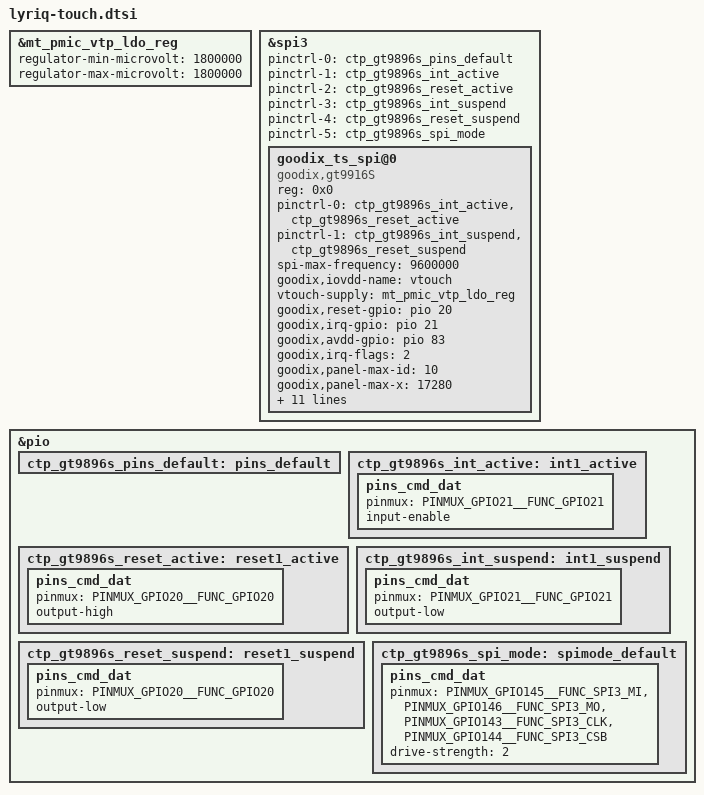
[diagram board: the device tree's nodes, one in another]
/* SPDX-License-Identifier: GPL-2.0 */
/*
 * Copyright (c) 2019 MediaTek Inc.
*/
/* TOUCH start */
&mt_pmic_vtp_ldo_reg {
	regulator-min-microvolt = <1800000>;
	regulator-max-microvolt = <1800000>;
//	regulator-boot-on;
//	regulator-always-on;
};

&spi3 {
	status = "okay";
	#address-cells = <1>;
	#size-cells = <0>;
	pinctrl-names = "default", "gt9896s_int_active",
		"gt9896s_reset_active", "gt9896s_int_suspend",
		"gt9896s_reset_suspend", "gt9896s_spi_mode";
	pinctrl-0 = <&ctp_gt9896s_pins_default>;
	pinctrl-1 = <&ctp_gt9896s_int_active>;
	pinctrl-2 = <&ctp_gt9896s_reset_active>;
	pinctrl-3 = <&ctp_gt9896s_int_suspend>;
	pinctrl-4 = <&ctp_gt9896s_reset_suspend>;
	pinctrl-5 = <&ctp_gt9896s_spi_mode>;

	goodix_ts_spi@0 {
		status = "ok";
		compatible = "goodix,gt9916S";
		reg = <0x0>;
		pinctrl-names = "pmx_ts_active", "pmx_ts_suspend";
		pinctrl-0 = <&ctp_gt9896s_int_active &ctp_gt9896s_reset_active>;
		pinctrl-1 = <&ctp_gt9896s_int_suspend &ctp_gt9896s_reset_suspend>;
		spi-max-frequency = <9600000>;  /* 4800000,9600000,15000000,19200000 */
		goodix,iovdd-name = "vtouch";
		vtouch-supply = <&mt_pmic_vtp_ldo_reg>;
		goodix,reset-gpio = <&pio 20 0x0>;
		goodix,irq-gpio = <&pio 21 0x0>;
		goodix,avdd-gpio = <&pio 83 0x0>;
		goodix,irq-flags = <2>; /* 1:rising, 2:falling;*/
		goodix,panel-max-id = <10>;
		goodix,panel-max-x = <17280>;
		goodix,panel-max-y = <38400>;
		goodix,panel-max-w = <256>;
		goodix,panel-max-p = <256>;
		goodix,input-max-x = <1080>;
		goodix,input-max-y = <2400>;
		goodix,edge-ctrl;
		mmi,enable-gestures;
		mmi,supported_gesture_type = <0x07>;
		mmi,power-off-suspend;
		mmi,usb-charger-detection;
		mmi,charger-psy-name = "battery";
	};
};

&pio {
	ctp_gt9896s_pins_default: pins_default {
	};
	ctp_gt9896s_int_active: int1_active {
		pins_cmd_dat {
			pinmux = <PINMUX_GPIO21__FUNC_GPIO21>;
			input-enable;
		};
	};
	ctp_gt9896s_reset_active: reset1_active {
		pins_cmd_dat {
			pinmux = <PINMUX_GPIO20__FUNC_GPIO20>;
			output-high;
		};
	};
	ctp_gt9896s_int_suspend: int1_suspend {
		pins_cmd_dat {
			pinmux = <PINMUX_GPIO21__FUNC_GPIO21>;
			output-low;
		};
	};
	ctp_gt9896s_reset_suspend: reset1_suspend {
		pins_cmd_dat {
			pinmux = <PINMUX_GPIO20__FUNC_GPIO20>;
			output-low;
		};
	};
	ctp_gt9896s_spi_mode: spimode_default {
		pins_cmd_dat {
			pinmux = <PINMUX_GPIO145__FUNC_SPI3_MI>,
				<PINMUX_GPIO146__FUNC_SPI3_MO>,
				<PINMUX_GPIO143__FUNC_SPI3_CLK>,
				<PINMUX_GPIO144__FUNC_SPI3_CSB>;
			drive-strength = <2>;
		};
	};
};
/* TOUCH end */
